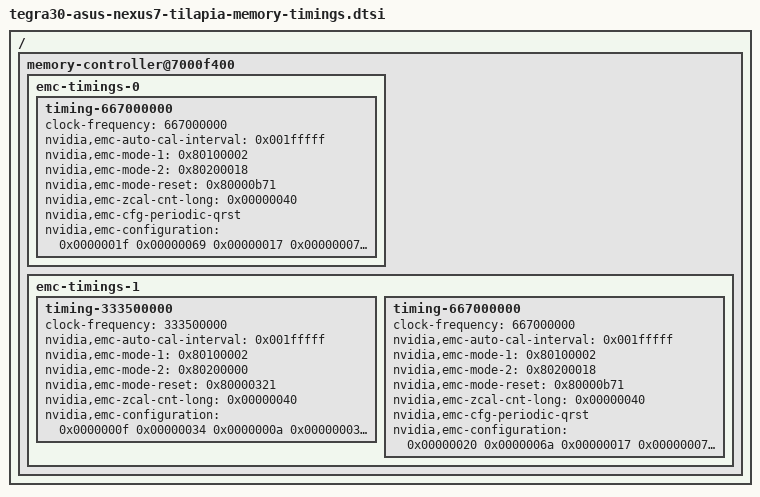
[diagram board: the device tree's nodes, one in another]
#include "tegra30-asus-nexus7-grouper-memory-timings.dtsi"
/ {
	memory-controller@7000f400 {
		emc-timings-0 {
			timing-667000000 {
				clock-frequency = <667000000>;
				nvidia,emc-auto-cal-interval = <0x001fffff>;
				nvidia,emc-mode-1 = <0x80100002>;
				nvidia,emc-mode-2 = <0x80200018>;
				nvidia,emc-mode-reset = <0x80000b71>;
				nvidia,emc-zcal-cnt-long = <0x00000040>;
				nvidia,emc-cfg-periodic-qrst;
				nvidia,emc-configuration = <
					0x0000001f  
					0x00000069  
					0x00000017  
					0x00000007  
					0x00000005  
					0x0000000c  
					0x00000003  
					0x00000011  
					0x00000007  
					0x00000007  
					0x00000002  
					0x00000001  
					0x00000000  
					0x00000007  
					0x0000000b  
					0x00000009  
					0x0000000b  
					0x00000011  
					0x00001412  
					0x00000000  
					0x00000504  
					0x00000002  
					0x0000000e  
					0x00000001  
					0x00000000  
					0x0000000c  
					0x00000016  
					0x00000072  
					0x00000200  
					0x00000005  
					0x00000015  
					0x00000000  
					0x00000006  
					0x00000007  
					0x00001453  
					0x0000000c  
					0x00000004  
					0x00000000  
					0x00000000  
					0x00005088  
					0xf00b0191  
					0x00008000  
					0x00000008  
					0x00000008  
					0x00000008  
					0x00000008  
					0x0000000a  
					0x0000000a  
					0x0000000a  
					0x0000000a  
					0x00000000  
					0x00000000  
					0x00000000  
					0x00000000  
					0x00000000  
					0x00000000  
					0x00000000  
					0x00000000  
					0x00000000  
					0x00000000  
					0x00000000  
					0x00000000  
					0x00000000  
					0x00000000  
					0x00000000  
					0x00000000  
					0x0000000c  
					0x0000000c  
					0x0000000c  
					0x0000000c  
					0x000002a0  
					0x0800013d  
					0x22220000  
					0x77fff884  
					0x01f1f501  
					0x07077404  
					0x54000000  
					0x080001e8  
					0x08000021  
					0x00000802  
					0x00020000  
					0x00000100  
					0x0156000c  
					0xa0f10000  
					0x00000000  
					0x00000000  
					0x800028a5  
					0xe8000000  
					0xff00ff49  
				>;
			};
		};
		emc-timings-1 {
			timing-333500000 {
				clock-frequency = <333500000>;
				nvidia,emc-auto-cal-interval = <0x001fffff>;
				nvidia,emc-mode-1 = <0x80100002>;
				nvidia,emc-mode-2 = <0x80200000>;
				nvidia,emc-mode-reset = <0x80000321>;
				nvidia,emc-zcal-cnt-long = <0x00000040>;
				nvidia,emc-configuration = <
					0x0000000f  
					0x00000034  
					0x0000000a  
					0x00000003  
					0x00000003  
					0x00000008  
					0x00000002  
					0x00000009  
					0x00000003  
					0x00000003  
					0x00000002  
					0x00000001  
					0x00000000  
					0x00000004  
					0x00000006  
					0x00000004  
					0x0000000a  
					0x0000000c  
					0x000009e9  
					0x00000000  
					0x0000027a  
					0x00000001  
					0x00000008  
					0x00000001  
					0x00000000  
					0x00000007  
					0x0000000e  
					0x00000039  
					0x00000200  
					0x00000004  
					0x0000000a  
					0x00000000  
					0x00000004  
					0x00000005  
					0x00000a2a  
					0x00000000  
					0x00000004  
					0x00000000  
					0x00000000  
					0x00007088  
					0x002600a4  
					0x00008000  
					0x0003c000  
					0x0003c000  
					0x0003c000  
					0x0003c000  
					0x00014000  
					0x00014000  
					0x00014000  
					0x00014000  
					0x00000000  
					0x00000000  
					0x00000000  
					0x00000000  
					0x00000000  
					0x00000000  
					0x00000000  
					0x00000000  
					0x00000000  
					0x00000000  
					0x00000000  
					0x00000000  
					0x00000000  
					0x00000000  
					0x00000000  
					0x00000000  
					0x00048000  
					0x00048000  
					0x00048000  
					0x00048000  
					0x000002a0  
					0x0800013d  
					0x00000000  
					0x77fff884  
					0x01f1f508  
					0x05057404  
					0x54000007  
					0x080001e8  
					0x08000021  
					0x00000802  
					0x00020000  
					0x00000100  
					0x018b000c  
					0xa0f10000  
					0x00000000  
					0x00000000  
					0x800014d4  
					0xe8000000  
					0xff00ff89  
				>;
			};
			timing-667000000 {
				clock-frequency = <667000000>;
				nvidia,emc-auto-cal-interval = <0x001fffff>;
				nvidia,emc-mode-1 = <0x80100002>;
				nvidia,emc-mode-2 = <0x80200018>;
				nvidia,emc-mode-reset = <0x80000b71>;
				nvidia,emc-zcal-cnt-long = <0x00000040>;
				nvidia,emc-cfg-periodic-qrst;
				nvidia,emc-configuration = <
					0x00000020  
					0x0000006a  
					0x00000017  
					0x00000007  
					0x00000005  
					0x0000000c  
					0x00000003  
					0x00000011  
					0x00000007  
					0x00000007  
					0x00000002  
					0x00000001  
					0x00000000  
					0x00000007  
					0x0000000a  
					0x00000009  
					0x0000000b  
					0x00000011  
					0x00001412  
					0x00000000  
					0x00000504  
					0x00000002  
					0x0000000e  
					0x00000001  
					0x00000000  
					0x0000000c  
					0x00000016  
					0x00000072  
					0x00000200  
					0x00000005  
					0x00000015  
					0x00000000  
					0x00000006  
					0x00000007  
					0x00001453  
					0x0000000b  
					0x00000006  
					0x00000000  
					0x00000000  
					0x00005088  
					0xf00b0191  
					0x00008000  
					0x00000008  
					0x00000008  
					0x00000008  
					0x00000008  
					0x0000000a  
					0x0000000a  
					0x0000000a  
					0x0000000a  
					0x00018000  
					0x00018000  
					0x00018000  
					0x00018000  
					0x00000000  
					0x00000000  
					0x00000000  
					0x00000000  
					0x00000000  
					0x00000000  
					0x00000000  
					0x00000000  
					0x00000000  
					0x00000000  
					0x00000000  
					0x00000000  
					0x0000000a  
					0x0000000a  
					0x0000000a  
					0x0000000a  
					0x000002a0  
					0x0800013d  
					0x22220000  
					0x77fff884  
					0x01f1f501  
					0x07077404  
					0x54000000  
					0x080001e8  
					0x0c000021  
					0x00000802  
					0x00020000  
					0x00000100  
					0x0155000c  
					0xa0f10000  
					0x00000000  
					0x00000000  
					0x800028a5  
					0xe8000000  
					0xff00ff49  
				>;
			};
		};
	};
};
